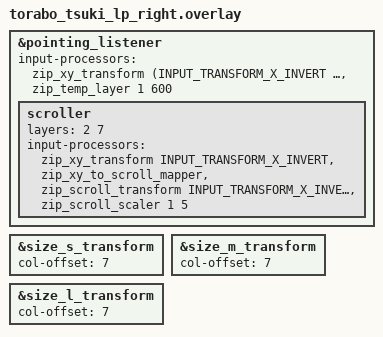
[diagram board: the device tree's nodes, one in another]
#include "torabo_tsuki_lp.dtsi"
#include <input/processors.dtsi>
#include <dt-bindings/zmk/input_transform.h>

//&pointing_listener {
//    input-processors = <&zip_xy_transform (INPUT_TRANSFORM_X_INVERT | INPUT_TRANSFORM_Y_INVERT)>;
//};
&pointing_listener {
    input-processors = 
        <&zip_xy_transform (INPUT_TRANSFORM_X_INVERT | INPUT_TRANSFORM_Y_INVERT)>,
        <&zip_temp_layer 1 600>;
    scroller {
        layers = <2 7>;
        input-processors = 
            <&zip_xy_transform INPUT_TRANSFORM_X_INVERT>,       //X軸反転
            <&zip_xy_to_scroll_mapper>,                         //スクロールモードに変更
            <&zip_scroll_transform INPUT_TRANSFORM_X_INVERT>,   //スクロールのX軸反転
            <&zip_scroll_scaler 1 5>;                           //スクロール量を1/5倍
    };
};

&size_s_transform {
    col-offset = <7>;
};

&size_m_transform {
    col-offset = <7>;
};

&size_l_transform {
    col-offset = <7>;
};

